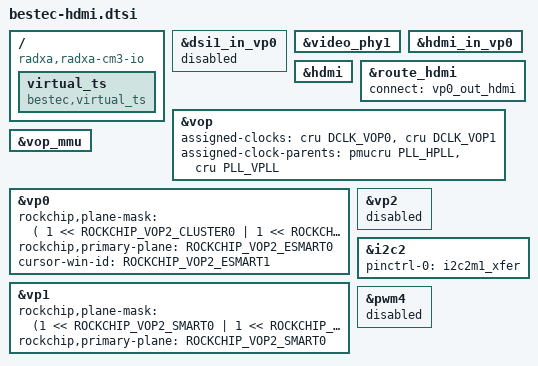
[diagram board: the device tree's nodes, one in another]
///dts-v1/;

#include <dt-bindings/display/media-bus-format.h>
#include <dt-bindings/display/drm_mipi_dsi.h>
#include <dt-bindings/display/rockchip_vop.h>
#include <dt-bindings/sensor-dev.h>
/ {
	compatible = "radxa,radxa-cm3-io", "rockchip,rk3566";

	virtual_ts: virtual_ts {
                compatible = "bestec,virtual_ts";
                status = "okay";
        };

};


&dsi1_in_vp0{
	status = "disabled";
};

&video_phy1{
	status = "okay";
};

&hdmi_in_vp0{
	status = "okay";
};

&hdmi{
	status = "okay";
};

&route_hdmi {
        status = "okay";
        connect = <&vp0_out_hdmi>;
};

&vop {
	assigned-clocks = <&cru DCLK_VOP0>, <&cru DCLK_VOP1>;
	assigned-clock-parents = <&pmucru PLL_HPLL>, <&cru PLL_VPLL>;
	status = "okay";
};

&vop_mmu {
	status = "okay";
};


&vp0 {
        rockchip,plane-mask = <(
                                1 << ROCKCHIP_VOP2_CLUSTER0 | 1 << ROCKCHIP_VOP2_ESMART0 |
                                1 << ROCKCHIP_VOP2_CLUSTER1 | 1 << ROCKCHIP_VOP2_ESMART1 )>;
        rockchip,primary-plane = <ROCKCHIP_VOP2_ESMART0>;
        cursor-win-id = <ROCKCHIP_VOP2_ESMART1>;
};


&vp1 {
        rockchip,plane-mask = <(1 << ROCKCHIP_VOP2_SMART0 | 1 << ROCKCHIP_VOP2_SMART1)>;
        rockchip,primary-plane = <ROCKCHIP_VOP2_SMART0>;
};

&vp2 {
        status = "disabled";
};

&i2c2{
	status = "okay";
	pinctrl-0 = <&i2c2m1_xfer>;
	#address-cells = <1>;
	#size-cells = <0>;

};

&pwm4{
	status = "disabled";
};

